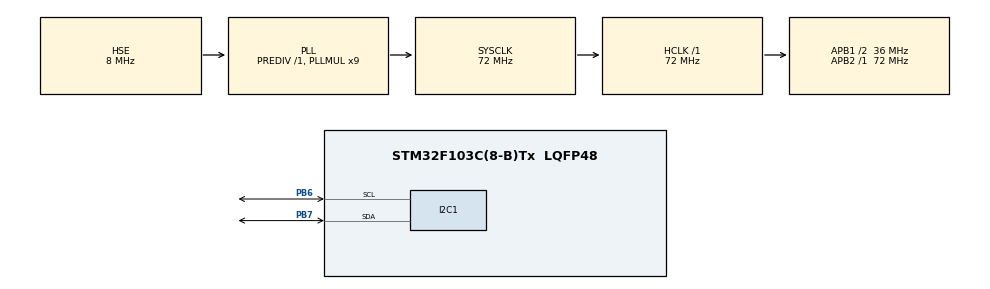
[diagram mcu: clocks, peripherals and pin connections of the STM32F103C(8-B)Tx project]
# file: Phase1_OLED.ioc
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Mcu.Family=STM32F1
Mcu.Name=STM32F103C(8-B)Tx
Mcu.Package=LQFP48
NVIC.PriorityGroup=NVIC_PRIORITYGROUP_4
PA13.Mode=Serial_Wire
PA13.Signal=SYS_JTMS-SWDIO
PA14.Mode=Serial_Wire
PA14.Signal=SYS_JTCK-SWCLK
PB6.Mode=I2C
PB6.Signal=I2C1_SCL
PB7.Mode=I2C
PB7.Signal=I2C1_SDA
PD0-OSC_IN.Mode=HSE-External-Oscillator
PD0-OSC_IN.Signal=RCC_OSC_IN
PD1-OSC_OUT.Mode=HSE-External-Oscillator
PD1-OSC_OUT.Signal=RCC_OSC_OUT
ProjectManager.HeapSize=0x200
ProjectManager.StackSize=0x400
ProjectManager.TargetToolchain=CMake
RCC.AHBFreq_Value=72000000
RCC.APB1CLKDivider=RCC_HCLK_DIV2
RCC.APB1Freq_Value=36000000
RCC.APB1TimFreq_Value=72000000
RCC.APB2Freq_Value=72000000
RCC.APB2TimFreq_Value=72000000
RCC.HCLKFreq_Value=72000000
RCC.PLLMUL=RCC_PLL_MUL9
RCC.PLLSourceVirtual=RCC_PLLSOURCE_HSE
RCC.SYSCLKFreq_VALUE=72000000
RCC.SYSCLKSource=RCC_SYSCLKSOURCE_PLLCLK
RCC.USBFreq_Value=72000000
board=custom

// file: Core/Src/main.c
/* USER CODE BEGIN Header */
/**
  ******************************************************************************
  * @file           : main.c
  * @brief          : Main program body
  ******************************************************************************
  * @attention
  *
  * Copyright (c) 2026 STMicroelectronics.
  * All rights reserved.
  *
  * This software is licensed under terms that can be found in the LICENSE file
  * in the root directory of this software component.
  * If no LICENSE file comes with this software, it is provided AS-IS.
  *
  ******************************************************************************
  */
/* USER CODE END Header */
#include "main.h"
#include "i2c.h"
#include "gpio.h"

/* USER CODE BEGIN Includes */
#include "oled.h"
#include "smartwatch_ui.h"
/* USER CODE END Includes */

/* USER CODE BEGIN PV */
SmartWatchData_t watch_data;
UIPage_t current_page = PAGE_WATCH_FACE;
uint32_t last_switch_tick = 0;
/* USER CODE END PV */

void SystemClock_Config(void);

int main(void)
{

  /* MCU Configuration--------------------------------------------------------*/

  /* Reset of all peripherals, Initializes the Flash interface and the Systick. */
  HAL_Init();

  /* Configure the system clock */
  SystemClock_Config();

  /* Initialize all configured peripherals */
  MX_GPIO_Init();
  MX_I2C1_Init();
  /* USER CODE BEGIN 2 */

  /* Initialize OLED */
  OLED_Init();

  /* Initialize demo data */
  UI_InitData(&watch_data);

  /* Draw initial page */
  UI_DrawPage(current_page, &watch_data);
  last_switch_tick = HAL_GetTick();

  /* USER CODE END 2 */

  /* Infinite loop */
  while (1)
  {

    /* USER CODE BEGIN 3 */
    uint32_t now = HAL_GetTick();

    /* Simulate time passing (update every second) */
    if (now - last_switch_tick >= 1000) {
        watch_data.second++;
        if (watch_data.second >= 60) {
            watch_data.second = 0;
            watch_data.minute++;
            if (watch_data.minute >= 60) {
                watch_data.minute = 0;
                watch_data.hour++;
                if (watch_data.hour >= 24) {
                    watch_data.hour = 0;
                }
            }
        }

        /* Simulate heart rate variation */
        watch_data.heart_rate = 75 + (now % 20) - 10;

        /* Simulate battery drain */
        if (now % 60000 < 1000) {
            if (watch_data.battery_pct > 0)
                watch_data.battery_pct--;
        }

        /* Switch page every 4 seconds */
        if ((now / 1000) % 4 == 0) {
            UIPage_t next = (UIPage_t)(((uint8_t)current_page + 1) % PAGE_MAX);
            if (next != current_page) {
                current_page = next;
            }
        }

        /* Redraw current page */
        UI_DrawPage(current_page, &watch_data);

        last_switch_tick = now;
    }

    /* Heart rate simulation: update every second on HR page */
    if (current_page == PAGE_HEART_RATE) {
        /* HR variation already handled above */
    }
  }
  /* USER CODE END 3 */
}

void SystemClock_Config(void)
{
  RCC_OscInitTypeDef RCC_OscInitStruct = {0};
  RCC_ClkInitTypeDef RCC_ClkInitStruct = {0};

  /** Initializes the RCC Oscillators according to the specified parameters
  * in the RCC_OscInitTypeDef structure.
  */
  RCC_OscInitStruct.OscillatorType = RCC_OSCILLATORTYPE_HSE;
  RCC_OscInitStruct.HSEState = RCC_HSE_ON;
  RCC_OscInitStruct.HSEPredivValue = RCC_HSE_PREDIV_DIV1;
  RCC_OscInitStruct.HSIState = RCC_HSI_ON;
  RCC_OscInitStruct.PLL.PLLState = RCC_PLL_ON;
  RCC_OscInitStruct.PLL.PLLSource = RCC_PLLSOURCE_HSE;
  RCC_OscInitStruct.PLL.PLLMUL = RCC_PLL_MUL9;
  if (HAL_RCC_OscConfig(&RCC_OscInitStruct) != HAL_OK)
  {
    Error_Handler();
  }

  /** Initializes the CPU, AHB and APB buses clocks
  */
  RCC_ClkInitStruct.ClockType = RCC_CLOCKTYPE_HCLK|RCC_CLOCKTYPE_SYSCLK
                              |RCC_CLOCKTYPE_PCLK1|RCC_CLOCKTYPE_PCLK2;
  RCC_ClkInitStruct.SYSCLKSource = RCC_SYSCLKSOURCE_PLLCLK;
  RCC_ClkInitStruct.AHBCLKDivider = RCC_SYSCLK_DIV1;
  RCC_ClkInitStruct.APB1CLKDivider = RCC_HCLK_DIV2;
  RCC_ClkInitStruct.APB2CLKDivider = RCC_HCLK_DIV1;

  if (HAL_RCC_ClockConfig(&RCC_ClkInitStruct, FLASH_LATENCY_2) != HAL_OK)
  {
    Error_Handler();
  }
}

void Error_Handler(void)
{
  __disable_irq();
  while (1)
  {
  }
}
